AUTOSAR XML (schema 4-2-2)
package /STELLANTIS/EPT/ASWCs
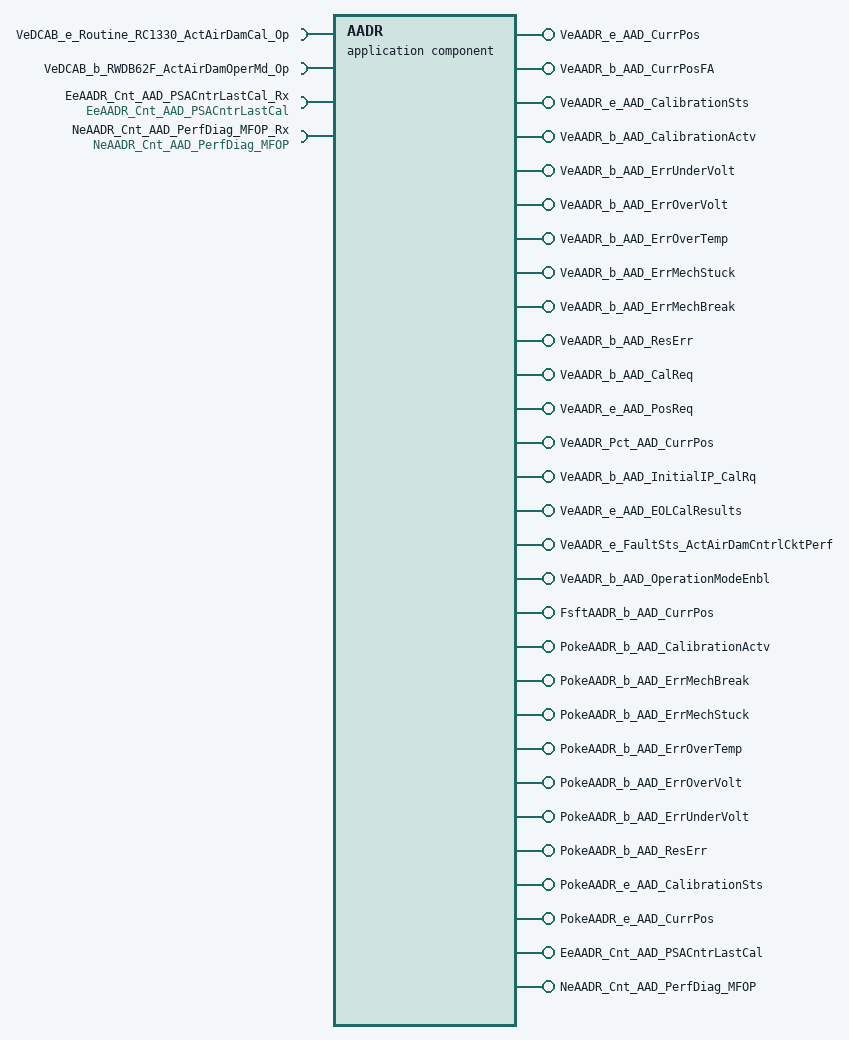
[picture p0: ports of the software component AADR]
  application sw component type AADR
    require port VeDCAB_e_Routine_RC1330_ActAirDamCal_Op: nonqueued-receiver-com-spec{data-element=Value, init-value=CeDCAB_e_Routine_NOP}, required-interface=VeDCAB_e_Routine_RC1330_ActAirDamCal_Op
    require port VeDCAB_b_RWDB62F_ActAirDamOperMd_Op: nonqueued-receiver-com-spec{data-element=Value, init-value=0}, required-interface=VeDCAB_b_RWDB62F_ActAirDamOperMd_Op
    27 x provide port:
      VeAADR_e_AAD_CurrPos: nonqueued-sender-com-spec{data-element=Value, init-value=CeAADR_e_SNA}, provided-interface=VeAADR_e_AAD_CurrPos
      VeAADR_b_AAD_CurrPosFA: nonqueued-sender-com-spec{data-element=Value, init-value=0}, provided-interface=VeAADR_b_AAD_CurrPosFA
      VeAADR_e_AAD_CalibrationSts: nonqueued-sender-com-spec{data-element=Value, init-value=CeAADR_e_AAD_Calibrated}, provided-interface=VeAADR_e_AAD_CalibrationSts
      VeAADR_b_AAD_CalibrationActv: nonqueued-sender-com-spec{data-element=Value, init-value=0}, provided-interface=VeAADR_b_AAD_CalibrationActv
      VeAADR_b_AAD_ErrUnderVolt: nonqueued-sender-com-spec{data-element=Value, init-value=0}, provided-interface=VeAADR_b_AAD_ErrUnderVolt
      VeAADR_b_AAD_ErrOverVolt: nonqueued-sender-com-spec{data-element=Value, init-value=0}, provided-interface=VeAADR_b_AAD_ErrOverVolt
      VeAADR_b_AAD_ErrOverTemp: nonqueued-sender-com-spec{data-element=Value, init-value=0}, provided-interface=VeAADR_b_AAD_ErrOverTemp
      VeAADR_b_AAD_ErrMechStuck: nonqueued-sender-com-spec{data-element=Value, init-value=0}, provided-interface=VeAADR_b_AAD_ErrMechStuck
      VeAADR_b_AAD_ErrMechBreak: nonqueued-sender-com-spec{data-element=Value, init-value=0}, provided-interface=VeAADR_b_AAD_ErrMechBreak
      VeAADR_b_AAD_ResErr: nonqueued-sender-com-spec{data-element=Value, init-value=0}, provided-interface=VeAADR_b_AAD_ResErr
      VeAADR_b_AAD_CalReq: nonqueued-sender-com-spec{data-element=Value, init-value=0}, provided-interface=VeAADR_b_AAD_CalReq
      VeAADR_e_AAD_PosReq: nonqueued-sender-com-spec{data-element=Value, init-value=CeAADR_e_SNA}, provided-interface=VeAADR_e_AAD_PosReq
      VeAADR_Pct_AAD_CurrPos: nonqueued-sender-com-spec{data-element=Value, init-value=0}, provided-interface=VeAADR_Pct_AAD_CurrPos
      VeAADR_b_AAD_InitialIP_CalRq: nonqueued-sender-com-spec{data-element=Value, init-value=0}, provided-interface=VeAADR_b_AAD_InitialIP_CalRq
      VeAADR_e_AAD_EOLCalResults: nonqueued-sender-com-spec{data-element=Value, init-value=CeAADR_e_AAD_CalInProgress}, provided-interface=VeAADR_e_AAD_EOLCalResults
      VeAADR_e_FaultSts_ActAirDamCntrlCktPerf: nonqueued-sender-com-spec{data-element=Value, init-value=CeDFIB_e_Init}, provided-interface=VeAADR_e_FaultSts_ActAirDamCntrlCktPerf
      VeAADR_b_AAD_OperationModeEnbl: nonqueued-sender-com-spec{data-element=Value, init-value=0}, provided-interface=VeAADR_b_AAD_OperationModeEnbl
      FsftAADR_b_AAD_CurrPos: server-com-spec=FsftAADR_b_AAD_CurrPos, provided-interface=FsftAADR_b_AAD_CurrPos
      PokeAADR_b_AAD_CalibrationActv: server-com-spec{operation=PokeAADR_b_AAD_CalibrationActv, queue-length=1}, provided-interface=PokeAADR_b_AAD_CalibrationActv
      PokeAADR_b_AAD_ErrMechBreak: server-com-spec{operation=PokeAADR_b_AAD_ErrMechBreak, queue-length=1}, provided-interface=PokeAADR_b_AAD_ErrMechBreak
      PokeAADR_b_AAD_ErrMechStuck: server-com-spec{operation=PokeAADR_b_AAD_ErrMechStuck, queue-length=1}, provided-interface=PokeAADR_b_AAD_ErrMechStuck
      PokeAADR_b_AAD_ErrOverTemp: server-com-spec{operation=PokeAADR_b_AAD_ErrOverTemp, queue-length=1}, provided-interface=PokeAADR_b_AAD_ErrOverTemp
      PokeAADR_b_AAD_ErrOverVolt: server-com-spec{operation=PokeAADR_b_AAD_ErrOverVolt, queue-length=1}, provided-interface=PokeAADR_b_AAD_ErrOverVolt
      PokeAADR_b_AAD_ErrUnderVolt: server-com-spec{operation=PokeAADR_b_AAD_ErrUnderVolt, queue-length=1}, provided-interface=PokeAADR_b_AAD_ErrUnderVolt
      PokeAADR_b_AAD_ResErr: server-com-spec{operation=PokeAADR_b_AAD_ResErr, queue-length=1}, provided-interface=PokeAADR_b_AAD_ResErr
      PokeAADR_e_AAD_CalibrationSts: server-com-spec{operation=PokeAADR_e_AAD_CalibrationSts, queue-length=1}, provided-interface=PokeAADR_e_AAD_CalibrationSts
      PokeAADR_e_AAD_CurrPos: server-com-spec{operation=PokeAADR_e_AAD_CurrPos, queue-length=1}, provided-interface=PokeAADR_e_AAD_CurrPos
    require port EeAADR_Cnt_AAD_PSACntrLastCal_Rx: nv-require-com-spec{init-value=0, variable=EeAADR_Cnt_AAD_PSACntrLastCal}, required-interface=EeAADR_Cnt_AAD_PSACntrLastCal
    require port NeAADR_Cnt_AAD_PerfDiag_MFOP_Rx: nv-require-com-spec{init-value=0, variable=NeAADR_Cnt_AAD_PerfDiag_MFOP}, required-interface=NeAADR_Cnt_AAD_PerfDiag_MFOP
    provide port EeAADR_Cnt_AAD_PSACntrLastCal: nv-provide-com-spec{ram-block-init-value=0, variable=EeAADR_Cnt_AAD_PSACntrLastCal}, provided-interface=EeAADR_Cnt_AAD_PSACntrLastCal
    provide port NeAADR_Cnt_AAD_PerfDiag_MFOP: nv-provide-com-spec{ram-block-init-value=0, variable=NeAADR_Cnt_AAD_PerfDiag_MFOP}, provided-interface=NeAADR_Cnt_AAD_PerfDiag_MFOP
    behavior IB_AADR: data-type-mapping=msADTtoIDTMapping, handle-termination-and-restart=NO-SUPPORT
      init event Event_AADR_ac_Init: start-on-event=AADR_ac_Init
      init event Event_PwrOn: start-on-event=AADR_PwrOn
      init event Event_PwrOff: start-on-event=AADR_PwrOff
      data received event Event_Routine_RC1330_ActAirDamCal: start-on-event=Routine_RC1330_ActAirDamCal, data=VeDCAB_e_Routine_RC1330_ActAirDamCal_Op.Value
      data received event Event_DidWrite_RWDB62F_ActAirDamOperMd: start-on-event=DidWrite_RWDB62F_ActAirDamOperMd, data=VeDCAB_b_RWDB62F_ActAirDamOperMd_Op.Value
      explicit-inter-runnable-variables:
        11 x data, all with category=VALUE, sw-calibration-access=READ-ONLY:
          AAD_CalibrationSts_Init_write_IRV: type=TeAADR_e_AAD_Calibration_Sts, init-value=CeAADR_e_AAD_Calibrated
          e_AAD_CurrPos_Init_write_IRV: type=TeAADR_e_AAD_Pos, init-value=CeAADR_e_SNA
          AAD_ErrOverVolt_Init_write_IRV: type=Boolean, init-value=0
          AAD_ErrUnderVolt_Init_write_IRV: type=Boolean, init-value=0
          AAD_ErrOverTemp_Init_write_IRV: type=Boolean, init-value=0
          EOL_AAD_PstnCmnd_Init_write_IRV: type=TeAADR_e_AAD_Pos, init-value=CeAADR_e_SNA
          EOL_AAD_IO_CntrlSt_Init_write_IRV: type=TeTAIR_e_IO_CntrlSt, init-value=CeTAIR_e_Return_Control_to_ECU
          AAD_CalibrationActv_Init_write_IRV: type=Boolean, init-value=0
          AAD_ErrMechBreak_Init_write_IRV: type=Boolean, init-value=0
          AAD_ErrMechStuck_Init_write_IRV: type=Boolean, init-value=0
          EOL_AAD_OperationModeEnbl_Init_write_IRV: type=Boolean, init-value=0
      5 x runnable:
        AADR_ac_Init
          data-send-points:
            5 x access:
              OUT_VeAADR_e_AAD_CurrPos_Value: accessed-variable=VeAADR_e_AAD_CurrPos.Value
              OUT_VeAADR_e_AAD_CalibrationSts_Value: accessed-variable=VeAADR_e_AAD_CalibrationSts.Value
              OUT_VeAADR_e_AAD_PosReq_Value: accessed-variable=VeAADR_e_AAD_PosReq.Value
              OUT_VeAADR_e_AAD_EOLCalResults_Value: accessed-variable=VeAADR_e_AAD_EOLCalResults.Value
              OUT_VeAADR_e_FaultSts_ActAirDamCntrlCktPerf_Value: accessed-variable=VeAADR_e_FaultSts_ActAirDamCntrlCktPerf.Value
        AADR_PwrOn
          data-receive-point-by-arguments:
            access IN_EeAADR_Cnt_AAD_PSACntrLastCal_Rx_EeAADR_Cnt_AAD_PSACntrLastCal: accessed-variable=EeAADR_Cnt_AAD_PSACntrLastCal_Rx.EeAADR_Cnt_AAD_PSACntrLastCal
            access IN_NeAADR_Cnt_AAD_PerfDiag_MFOP_Rx_NeAADR_Cnt_AAD_PerfDiag_MFOP: accessed-variable=NeAADR_Cnt_AAD_PerfDiag_MFOP_Rx.NeAADR_Cnt_AAD_PerfDiag_MFOP
          data-send-points:
            17 x access:
              OUT_VeAADR_b_AAD_CalibrationActv_Value: accessed-variable=VeAADR_b_AAD_CalibrationActv.Value
              OUT_VeAADR_e_AAD_CalibrationSts_Value: accessed-variable=VeAADR_e_AAD_CalibrationSts.Value
              OUT_VeAADR_e_AAD_CurrPos_Value: accessed-variable=VeAADR_e_AAD_CurrPos.Value
              OUT_VeAADR_b_AAD_CurrPosFA_Value: accessed-variable=VeAADR_b_AAD_CurrPosFA.Value
              OUT_VeAADR_Pct_AAD_CurrPos_Value: accessed-variable=VeAADR_Pct_AAD_CurrPos.Value
              OUT_VeAADR_b_AAD_ErrMechBreak_Value: accessed-variable=VeAADR_b_AAD_ErrMechBreak.Value
              OUT_VeAADR_b_AAD_ErrMechStuck_Value: accessed-variable=VeAADR_b_AAD_ErrMechStuck.Value
              OUT_VeAADR_b_AAD_ErrOverTemp_Value: accessed-variable=VeAADR_b_AAD_ErrOverTemp.Value
              OUT_VeAADR_b_AAD_ErrOverVolt_Value: accessed-variable=VeAADR_b_AAD_ErrOverVolt.Value
              OUT_VeAADR_b_AAD_ErrUnderVolt_Value: accessed-variable=VeAADR_b_AAD_ErrUnderVolt.Value
              OUT_VeAADR_b_AAD_ResErr_Value: accessed-variable=VeAADR_b_AAD_ResErr.Value
              OUT_VeAADR_b_AAD_CalReq_Value: accessed-variable=VeAADR_b_AAD_CalReq.Value
              OUT_VeAADR_e_AAD_PosReq_Value: accessed-variable=VeAADR_e_AAD_PosReq.Value
              OUT_VeAADR_b_AAD_InitialIP_CalRq_Value: accessed-variable=VeAADR_b_AAD_InitialIP_CalRq.Value
              OUT_VeAADR_e_AAD_EOLCalResults_Value: accessed-variable=VeAADR_e_AAD_EOLCalResults.Value
              OUT_VeAADR_e_FaultSts_ActAirDamCntrlCktPerf_Value: accessed-variable=VeAADR_e_FaultSts_ActAirDamCntrlCktPerf.Value
              OUT_VeAADR_b_AAD_OperationModeEnbl_Value: accessed-variable=VeAADR_b_AAD_OperationModeEnbl.Value
          written-local-variables:
            11 x access:
              WV_AAD_CalibrationActv_Init_write_IRV: accessed-variable=AAD_CalibrationActv_Init_write_IRV
              WV_AAD_CalibrationSts_Init_write_IRV: accessed-variable=AAD_CalibrationSts_Init_write_IRV
              WV_AAD_ErrMechBreak_Init_write_IRV: accessed-variable=AAD_ErrMechBreak_Init_write_IRV
              WV_AAD_ErrMechStuck_Init_write_IRV: accessed-variable=AAD_ErrMechStuck_Init_write_IRV
              WV_AAD_ErrOverTemp_Init_write_IRV: accessed-variable=AAD_ErrOverTemp_Init_write_IRV
              WV_AAD_ErrOverVolt_Init_write_IRV: accessed-variable=AAD_ErrOverVolt_Init_write_IRV
              WV_AAD_ErrUnderVolt_Init_write_IRV: accessed-variable=AAD_ErrUnderVolt_Init_write_IRV
              WV_EOL_AAD_IO_CntrlSt_Init_write_IRV: accessed-variable=EOL_AAD_IO_CntrlSt_Init_write_IRV
              WV_EOL_AAD_OperationModeEnbl_Init_write_IRV: accessed-variable=EOL_AAD_OperationModeEnbl_Init_write_IRV
              WV_EOL_AAD_PstnCmnd_Init_write_IRV: accessed-variable=EOL_AAD_PstnCmnd_Init_write_IRV
              WV_e_AAD_CurrPos_Init_write_IRV: accessed-variable=e_AAD_CurrPos_Init_write_IRV
        AADR_PwrOff
          data-send-points:
            access OUT_EeAADR_Cnt_AAD_PSACntrLastCal_EeAADR_Cnt_AAD_PSACntrLastCal: accessed-variable=EeAADR_Cnt_AAD_PSACntrLastCal.EeAADR_Cnt_AAD_PSACntrLastCal
            access OUT_NeAADR_Cnt_AAD_PerfDiag_MFOP_NeAADR_Cnt_AAD_PerfDiag_MFOP: accessed-variable=NeAADR_Cnt_AAD_PerfDiag_MFOP.NeAADR_Cnt_AAD_PerfDiag_MFOP
        Routine_RC1330_ActAirDamCal
          data-receive-point-by-arguments:
            access IN_VeDCAB_e_Routine_RC1330_ActAirDamCal_Op_Value: accessed-variable=VeDCAB_e_Routine_RC1330_ActAirDamCal_Op.Value
        DidWrite_RWDB62F_ActAirDamOperMd
          data-receive-point-by-arguments:
            access IN_VeDCAB_b_RWDB62F_ActAirDamOperMd_Op_Value: accessed-variable=VeDCAB_b_RWDB62F_ActAirDamOperMd_Op.Value
          data-send-points:
            access OUT_VeAADR_b_AAD_OperationModeEnbl_Value: accessed-variable=VeAADR_b_AAD_OperationModeEnbl.Value
          written-local-variables:
            access WV_EOL_AAD_OperationModeEnbl_Init_write_IRV: accessed-variable=EOL_AAD_OperationModeEnbl_Init_write_IRV
      variation point proxy Variant_AADR_1: category=CONDITION, condition-access=0
